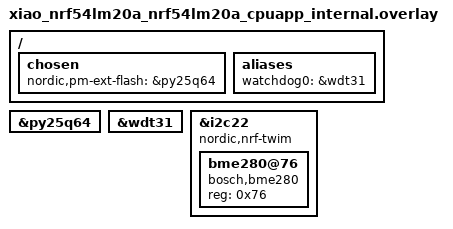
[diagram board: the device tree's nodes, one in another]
/*
 * Copyright (c) 2025 Nordic Semiconductor ASA
 *
 * SPDX-License-Identifier: LicenseRef-Nordic-5-Clause
 */

/ {
	chosen {
		nordic,pm-ext-flash = &py25q64;
	};
	aliases {
		/* Use watchdog wdt31 as the application watchdog */
		watchdog0 = &wdt31;
	};
};

&py25q64 {
	status = "okay";
};

&wdt31 {
	status = "okay";
};

&i2c22 {
	status = "okay";
	compatible = "nordic,nrf-twim";

	bme280@76 {
		compatible = "bosch,bme280";
		reg = <0x76>;
	};
};
